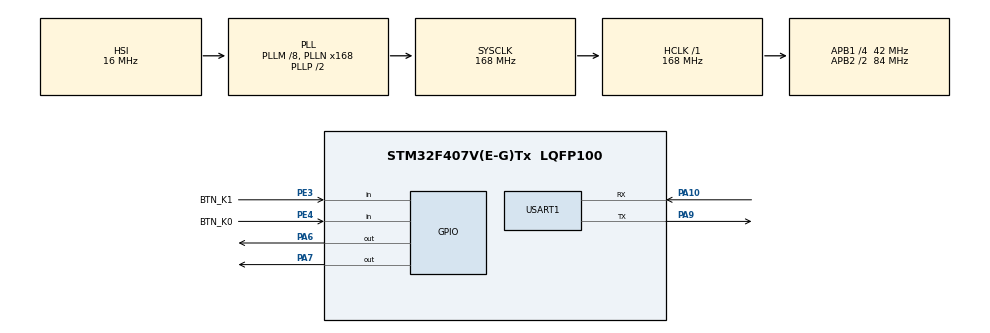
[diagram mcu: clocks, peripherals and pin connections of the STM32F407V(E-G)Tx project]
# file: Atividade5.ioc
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FREERTOS.Mutexes01=uartMutex,Dynamic,NULL,Available
FREERTOS.Tasks01=TaskSensor,24,128,TaskSensor_fun,Default,NULL,Dynamic,NULL,NULL;TaskControle,24,128,TaskControle_fun,Default,NULL,Dynamic,NULL,NULL
Mcu.Family=STM32F4
Mcu.Name=STM32F407V(E-G)Tx
Mcu.Package=LQFP100
NVIC.PriorityGroup=NVIC_PRIORITYGROUP_4
NVIC.TIM1_UP_TIM10_IRQn=true\:15\:0\:false\:false\:true\:false\:false\:true\:true
NVIC.TimeBase=TIM1_UP_TIM10_IRQn
NVIC.TimeBaseIP=TIM1
PA10.Mode=Asynchronous
PA10.Signal=USART1_RX
PA6.Signal=GPIO_Output
PA7.Signal=GPIO_Output
PA9.Mode=Asynchronous
PA9.Signal=USART1_TX
PE3.GPIO_Label=BTN_K1
PE3.GPIO_PuPd=GPIO_PULLUP
PE3.Signal=GPIO_Input
PE4.GPIO_Label=BTN_K0
PE4.GPIO_PuPd=GPIO_PULLUP
PE4.Signal=GPIO_Input
ProjectManager.HeapSize=0x200
ProjectManager.StackSize=0x400
ProjectManager.TargetToolchain=STM32CubeIDE
RCC.48MHZClocksFreq_Value=84000000
RCC.AHBFreq_Value=168000000
RCC.APB1CLKDivider=RCC_HCLK_DIV4
RCC.APB1Freq_Value=42000000
RCC.APB1TimFreq_Value=84000000
RCC.APB2CLKDivider=RCC_HCLK_DIV2
RCC.APB2Freq_Value=84000000
RCC.APB2TimFreq_Value=168000000
RCC.CortexFreq_Value=168000000
RCC.HCLKFreq_Value=168000000
RCC.HSE_VALUE=25000000
RCC.HSI_VALUE=16000000
RCC.LSE_VALUE=32768
RCC.PLLM=8
RCC.PLLN=168
RCC.SYSCLKFreq_VALUE=168000000
RCC.SYSCLKSource=RCC_SYSCLKSOURCE_PLLCLK
RCC.VCOOutputFreq_Value=336000000
USART1.VirtualMode=VM_ASYNC
VP_FREERTOS_VS_CMSIS_V2.Mode=CMSIS_V2
VP_SYS_VS_tim1.Mode=TIM1
board=custom

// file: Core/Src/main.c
/* USER CODE BEGIN Header */
/**
  ******************************************************************************
  * @file           : main.c
  * @brief          : Main program body
  ******************************************************************************
  * @attention
  *
  * Copyright (c) 2026 STMicroelectronics.
  * All rights reserved.
  *
  * This software is licensed under terms that can be found in the LICENSE file
  * in the root directory of this software component.
  * If no LICENSE file comes with this software, it is provided AS-IS.
  *
  ******************************************************************************
  */
/* USER CODE END Header */
#include "main.h"
#include "cmsis_os.h"

/* USER CODE BEGIN Includes */
#include <stdio.h>
#include <stdlib.h>
/* USER CODE END Includes */

UART_HandleTypeDef huart1;

/* Definitions for TaskSensor */
osThreadId_t TaskSensorHandle;
const osThreadAttr_t TaskSensor_attributes = {
  .name = "TaskSensor",
  .stack_size = 128 * 4,
  .priority = (osPriority_t) osPriorityNormal,
};
/* Definitions for TaskControle */
osThreadId_t TaskControleHandle;
const osThreadAttr_t TaskControle_attributes = {
  .name = "TaskControle",
  .stack_size = 128 * 4,
  .priority = (osPriority_t) osPriorityNormal,
};
/* Definitions for uartMutex */
osMutexId_t uartMutexHandle;
const osMutexAttr_t uartMutex_attributes = {
  .name = "uartMutex"
};

void SystemClock_Config(void);
static void MX_GPIO_Init(void);
static void MX_USART1_UART_Init(void);
void TaskSensor_fun(void *argument);
void TaskControle_fun(void *argument);

int main(void)
{

  /* MCU Configuration--------------------------------------------------------*/

  /* Reset of all peripherals, Initializes the Flash interface and the Systick. */
  HAL_Init();

  /* Configure the system clock */
  SystemClock_Config();

  /* Initialize all configured peripherals */
  MX_GPIO_Init();
  MX_USART1_UART_Init();

  /* Init scheduler */
  osKernelInitialize();
  /* Create the mutex(es) */
  /* creation of uartMutex */
  uartMutexHandle = osMutexNew(&uartMutex_attributes);

  /* Create the thread(s) */
  /* creation of TaskSensor */
  TaskSensorHandle = osThreadNew(TaskSensor_fun, NULL, &TaskSensor_attributes);

  /* creation of TaskControle */
  TaskControleHandle = osThreadNew(TaskControle_fun, NULL, &TaskControle_attributes);

  /* Start scheduler */
  osKernelStart();

  /* We should never get here as control is now taken by the scheduler */

  /* Infinite loop */
  while (1)
  {

  }
}

void SystemClock_Config(void)
{
  RCC_OscInitTypeDef RCC_OscInitStruct = {0};
  RCC_ClkInitTypeDef RCC_ClkInitStruct = {0};

  /** Configure the main internal regulator output voltage
  */
  __HAL_RCC_PWR_CLK_ENABLE();
  __HAL_PWR_VOLTAGESCALING_CONFIG(PWR_REGULATOR_VOLTAGE_SCALE1);

  /** Initializes the RCC Oscillators according to the specified parameters
  * in the RCC_OscInitTypeDef structure.
  */
  RCC_OscInitStruct.OscillatorType = RCC_OSCILLATORTYPE_HSI;
  RCC_OscInitStruct.HSIState = RCC_HSI_ON;
  RCC_OscInitStruct.HSICalibrationValue = RCC_HSICALIBRATION_DEFAULT;
  RCC_OscInitStruct.PLL.PLLState = RCC_PLL_ON;
  RCC_OscInitStruct.PLL.PLLSource = RCC_PLLSOURCE_HSI;
  RCC_OscInitStruct.PLL.PLLM = 8;
  RCC_OscInitStruct.PLL.PLLN = 168;
  RCC_OscInitStruct.PLL.PLLP = RCC_PLLP_DIV2;
  RCC_OscInitStruct.PLL.PLLQ = 4;
  if (HAL_RCC_OscConfig(&RCC_OscInitStruct) != HAL_OK)
  {
    Error_Handler();
  }

  /** Initializes the CPU, AHB and APB buses clocks
  */
  RCC_ClkInitStruct.ClockType = RCC_CLOCKTYPE_HCLK|RCC_CLOCKTYPE_SYSCLK
                              |RCC_CLOCKTYPE_PCLK1|RCC_CLOCKTYPE_PCLK2;
  RCC_ClkInitStruct.SYSCLKSource = RCC_SYSCLKSOURCE_PLLCLK;
  RCC_ClkInitStruct.AHBCLKDivider = RCC_SYSCLK_DIV1;
  RCC_ClkInitStruct.APB1CLKDivider = RCC_HCLK_DIV4;
  RCC_ClkInitStruct.APB2CLKDivider = RCC_HCLK_DIV2;

  if (HAL_RCC_ClockConfig(&RCC_ClkInitStruct, FLASH_LATENCY_5) != HAL_OK)
  {
    Error_Handler();
  }
}

static void MX_USART1_UART_Init(void)
{

  huart1.Instance = USART1;
  huart1.Init.BaudRate = 115200;
  huart1.Init.WordLength = UART_WORDLENGTH_8B;
  huart1.Init.StopBits = UART_STOPBITS_1;
  huart1.Init.Parity = UART_PARITY_NONE;
  huart1.Init.Mode = UART_MODE_TX_RX;
  huart1.Init.HwFlowCtl = UART_HWCONTROL_NONE;
  huart1.Init.OverSampling = UART_OVERSAMPLING_16;
  if (HAL_UART_Init(&huart1) != HAL_OK)
  {
    Error_Handler();
  }

}

static void MX_GPIO_Init(void)
{
  GPIO_InitTypeDef GPIO_InitStruct = {0};

  /* GPIO Ports Clock Enable */
  __HAL_RCC_GPIOE_CLK_ENABLE();
  __HAL_RCC_GPIOA_CLK_ENABLE();

  /*Configure GPIO pin Output Level */
  HAL_GPIO_WritePin(GPIOA, GPIO_PIN_6|GPIO_PIN_7, GPIO_PIN_RESET);

  /*Configure GPIO pins : BTN_K1_Pin BTN_K0_Pin */
  GPIO_InitStruct.Pin = BTN_K1_Pin|BTN_K0_Pin;
  GPIO_InitStruct.Mode = GPIO_MODE_INPUT;
  GPIO_InitStruct.Pull = GPIO_PULLUP;
  HAL_GPIO_Init(GPIOE, &GPIO_InitStruct);

  /*Configure GPIO pins : PA6 PA7 */
  GPIO_InitStruct.Pin = GPIO_PIN_6|GPIO_PIN_7;
  GPIO_InitStruct.Mode = GPIO_MODE_OUTPUT_PP;
  GPIO_InitStruct.Pull = GPIO_NOPULL;
  GPIO_InitStruct.Speed = GPIO_SPEED_FREQ_LOW;
  HAL_GPIO_Init(GPIOA, &GPIO_InitStruct);

}

/* USER CODE BEGIN 4 */
int _write(int file, char *ptr, int len) {
    // Transmite os dados recebidos pelo printf via UART
    HAL_UART_Transmit(&huart1, (uint8_t*)ptr, len, HAL_MAX_DELAY);
    return len;
}
/* USER CODE END 4 */

void TaskSensor_fun(void *argument)
{
  /* USER CODE BEGIN 5 */
  /* Infinite loop */
  for(;;)
  {
  osMutexAcquire ( uartMutexHandle , osWaitForever );
  for(int i = 0; i < 50; i++){
    printf("TASKSENSOR\r\n");
    }
  osMutexRelease(uartMutexHandle);

  }
  /* USER CODE END 5 */
}

void TaskControle_fun(void *argument)
{
  /* USER CODE BEGIN TaskControle_fun */
  /* Infinite loop */
  for(;;)
  {
  osMutexAcquire ( uartMutexHandle , osWaitForever );
  for(int i = 0; i < 50; i++){
		printf("TASKCONTROLE\r\n");
	}
  osMutexRelease(uartMutexHandle);

  }
  /* USER CODE END TaskControle_fun */
}

void HAL_TIM_PeriodElapsedCallback(TIM_HandleTypeDef *htim)
{
  if (htim->Instance == TIM1)
  {
    HAL_IncTick();
  }
}

void Error_Handler(void)
{
  __disable_irq();
  while (1)
  {
  }
}
